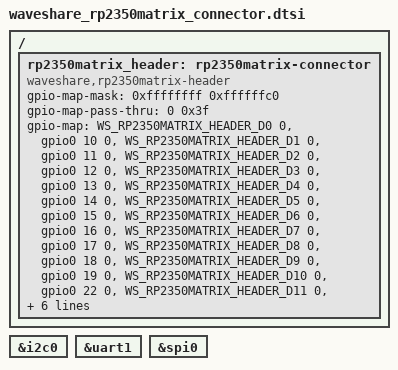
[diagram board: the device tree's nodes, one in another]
/*
 * SPDX-FileCopyrightText: Copyright (c) 2026 TiaC Systems
 * SPDX-License-Identifier: Apache-2.0
 */

#include <zephyr/dt-bindings/gpio/waveshare-rp2350matrix-header.h>

/ {
	rp2350matrix_header: rp2350matrix-connector {
		compatible = "waveshare,rp2350matrix-header";
		#gpio-cells = <2>;
		gpio-map-mask = <0xffffffff 0xffffffc0>;
		gpio-map-pass-thru = <0 0x3f>;
		gpio-map = <WS_RP2350MATRIX_HEADER_D0 0 &gpio0 10 0>,	/* GP10/PWM10 / UART-TX */
			   <WS_RP2350MATRIX_HEADER_D1 0 &gpio0 11 0>,	/* GP11/PWM11 / UART-RX */
			   <WS_RP2350MATRIX_HEADER_D2 0 &gpio0 12 0>,	/* GP12/PWM12 / I2C-SDA */
			   <WS_RP2350MATRIX_HEADER_D3 0 &gpio0 13 0>,	/* GP13/PWM13 / I2C-SCL */
			   <WS_RP2350MATRIX_HEADER_D4 0 &gpio0 14 0>,	/* GP14/PWM14 */
			   <WS_RP2350MATRIX_HEADER_D5 0 &gpio0 15 0>,	/* GP15/PWM15 */
			   <WS_RP2350MATRIX_HEADER_D6 0 &gpio0 16 0>,	/* GP16/PWM0 / SPI-CIPO */
			   <WS_RP2350MATRIX_HEADER_D7 0 &gpio0 17 0>,	/* GP17/PWM1 / SPI-CSn */
			   <WS_RP2350MATRIX_HEADER_D8 0 &gpio0 18 0>,	/* GP18/PWM2 / SPI-SCK */
			   <WS_RP2350MATRIX_HEADER_D9 0 &gpio0 19 0>,	/* GP19/PWM3 / SPI-COPI */
			   <WS_RP2350MATRIX_HEADER_D10 0 &gpio0 22 0>,	/* GP22/PWM6 */
			   <WS_RP2350MATRIX_HEADER_D11 0 &gpio0 23 0>,	/* GP23/PWM7 */
			   <WS_RP2350MATRIX_HEADER_D12 0 &gpio0 24 0>,	/* GP24/PWM8 */
			   <WS_RP2350MATRIX_HEADER_A0 0 &gpio0 26 0>,	/* GP26/PWM10 / A0 */
			   <WS_RP2350MATRIX_HEADER_A1 0 &gpio0 27 0>,	/* GP27/PWM11 / A1 */
			   <WS_RP2350MATRIX_HEADER_A2 0 &gpio0 28 0>,	/* GP28/PWM12 / A2 */
			   <WS_RP2350MATRIX_HEADER_A3 0 &gpio0 29 0>;	/* GP29/PWM13 / A3 */
	};
};

rp2350matrix_i2c: &i2c0 {};
rp2350matrix_serial: &uart1 {};
rp2350matrix_spi: &spi0 {};
